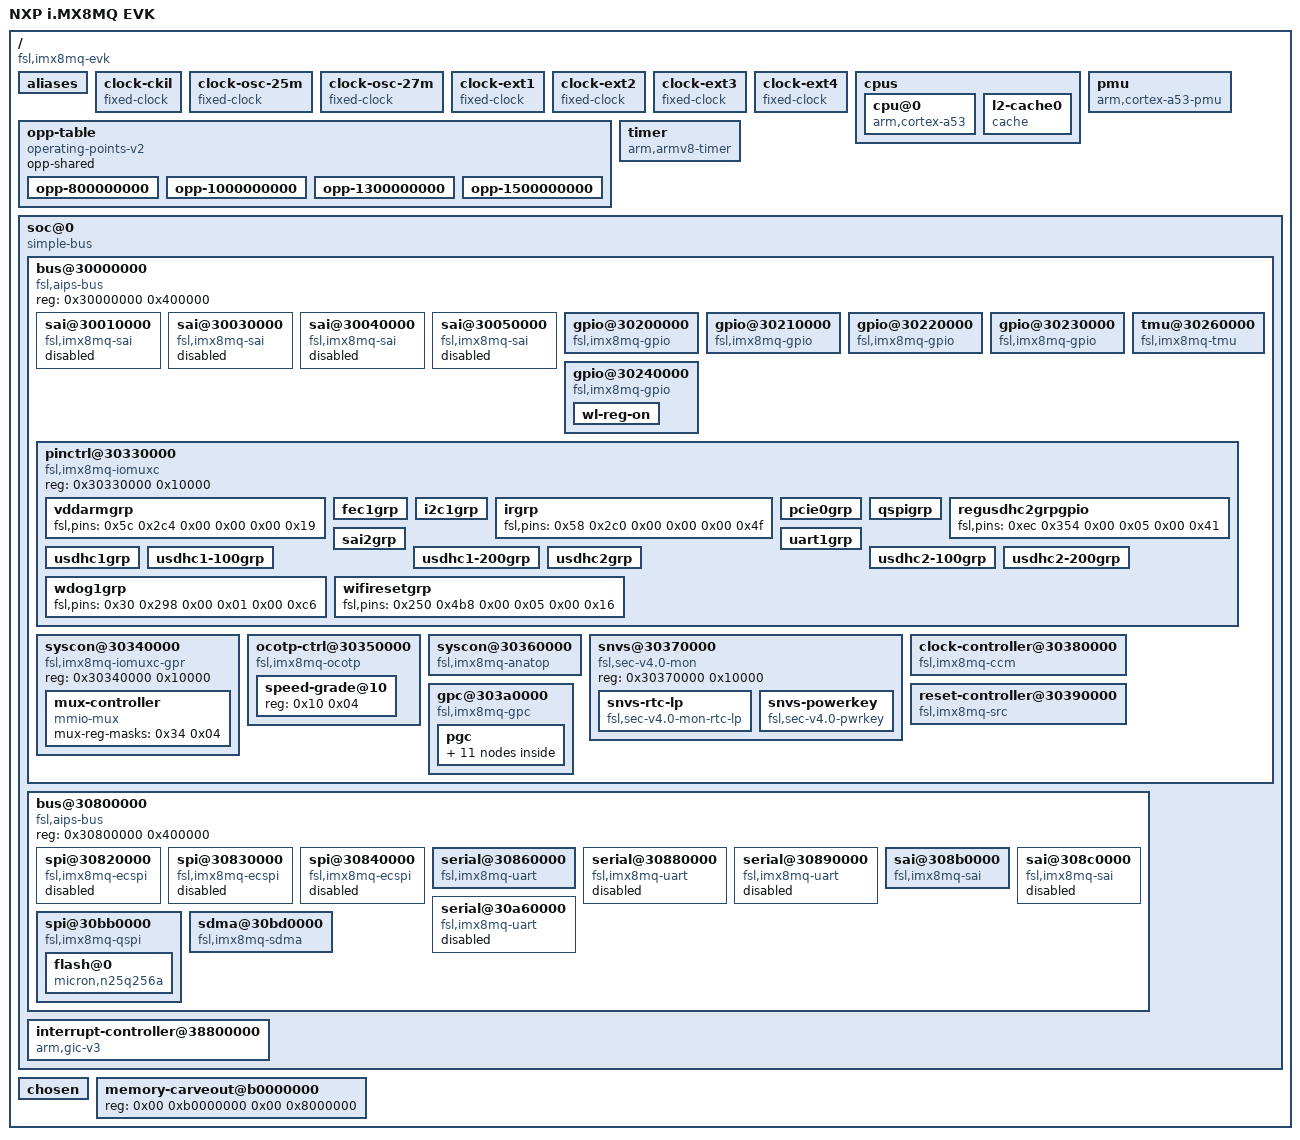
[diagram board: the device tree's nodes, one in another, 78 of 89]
/dts-v1/;

/ {
	interrupt-parent = <0x01>;
	#address-cells = <0x02>;
	#size-cells = <0x02>;
	model = "NXP i.MX8MQ EVK";
	compatible = "fsl,imx8mq-evk\0fsl,imx8mq";

	aliases {
		gpio0 = "/soc@0/bus@30000000/gpio@30200000";
		gpio1 = "/soc@0/bus@30000000/gpio@30210000";
		gpio2 = "/soc@0/bus@30000000/gpio@30220000";
		gpio3 = "/soc@0/bus@30000000/gpio@30230000";
		gpio4 = "/soc@0/bus@30000000/gpio@30240000";
		i2c0 = "/soc@0/bus@30800000/i2c@30a20000";
		i2c1 = "/soc@0/bus@30800000/i2c@30a30000";
		i2c2 = "/soc@0/bus@30800000/i2c@30a40000";
		i2c3 = "/soc@0/bus@30800000/i2c@30a50000";
		serial0 = "/soc@0/bus@30800000/serial@30860000";
		serial1 = "/soc@0/bus@30800000/serial@30890000";
		serial2 = "/soc@0/bus@30800000/serial@30880000";
		serial3 = "/soc@0/bus@30800000/serial@30a60000";
		spi0 = "/soc@0/bus@30800000/spi@30820000";
		spi1 = "/soc@0/bus@30800000/spi@30830000";
		spi2 = "/soc@0/bus@30800000/spi@30840000";
	};

	clock-ckil {
		compatible = "fixed-clock";
		#clock-cells = <0x00>;
		clock-frequency = <0x8000>;
		clock-output-names = "ckil";
		phandle = <0x16>;
	};

	clock-osc-25m {
		compatible = "fixed-clock";
		#clock-cells = <0x00>;
		clock-frequency = <0x17d7840>;
		clock-output-names = "osc_25m";
		phandle = <0x17>;
	};

	clock-osc-27m {
		compatible = "fixed-clock";
		#clock-cells = <0x00>;
		clock-frequency = <0x19bfcc0>;
		clock-output-names = "osc_27m";
		phandle = <0x18>;
	};

	clock-ext1 {
		compatible = "fixed-clock";
		#clock-cells = <0x00>;
		clock-frequency = <0x7ed6b40>;
		clock-output-names = "clk_ext1";
		phandle = <0x19>;
	};

	clock-ext2 {
		compatible = "fixed-clock";
		#clock-cells = <0x00>;
		clock-frequency = <0x7ed6b40>;
		clock-output-names = "clk_ext2";
		phandle = <0x1a>;
	};

	clock-ext3 {
		compatible = "fixed-clock";
		#clock-cells = <0x00>;
		clock-frequency = <0x7ed6b40>;
		clock-output-names = "clk_ext3";
		phandle = <0x1b>;
	};

	clock-ext4 {
		compatible = "fixed-clock";
		#clock-cells = <0x00>;
		clock-frequency = <0x7ed6b40>;
		clock-output-names = "clk_ext4";
		phandle = <0x1c>;
	};

	cpus {
		#address-cells = <0x01>;
		#size-cells = <0x00>;

		cpu@0 {
			device_type = "cpu";
			compatible = "arm,cortex-a53";
			reg = <0x00>;
			clock-latency = <0xee6c>;
			clocks = <0x02 0x102>;
			enable-method = "psci";
			next-level-cache = <0x03>;
			operating-points-v2 = <0x04>;
			#cooling-cells = <0x02>;
			nvmem-cells = <0x05>;
			nvmem-cell-names = "speed_grade";
			cpu-supply = <0x06>;
			phandle = <0x08>;
		};

		l2-cache0 {
			compatible = "cache";
			phandle = <0x03>;
		};
	};

	opp-table {
		compatible = "operating-points-v2";
		opp-shared;
		phandle = <0x04>;

		opp-800000000 {
			opp-hz = <0x00 0x2faf0800>;
			opp-microvolt = <0xdbba0>;
			opp-supported-hw = <0x0f 0x04>;
			clock-latency-ns = <0x249f0>;
			opp-suspend;
		};

		opp-1000000000 {
			opp-hz = <0x00 0x3b9aca00>;
			opp-microvolt = <0xdbba0>;
			opp-supported-hw = <0x0e 0x03>;
			clock-latency-ns = <0x249f0>;
			opp-suspend;
		};

		opp-1300000000 {
			opp-hz = <0x00 0x4d7c6d00>;
			opp-microvolt = <0xf4240>;
			opp-supported-hw = <0x0c 0x04>;
			clock-latency-ns = <0x249f0>;
			opp-suspend;
		};

		opp-1500000000 {
			opp-hz = <0x00 0x59682f00>;
			opp-microvolt = <0xf4240>;
			opp-supported-hw = <0x08 0x03>;
			clock-latency-ns = <0x249f0>;
			opp-suspend;
		};
	};

	pmu {
		compatible = "arm,cortex-a53-pmu";
		interrupts = <0x01 0x07 0x04>;
		interrupt-parent = <0x07>;
		interrupt-affinity = <0x08 0x09 0x0a 0x0b>;
	};

	timer {
		compatible = "arm,armv8-timer";
		interrupts = <0x01 0x0d 0x08 0x01 0x0e 0x08 0x01 0x0b 0x08 0x01 0x0a 0x08>;
		interrupt-parent = <0x07>;
		arm,no-tick-in-suspend;
	};

	soc@0 {
		compatible = "simple-bus";
		#address-cells = <0x01>;
		#size-cells = <0x01>;
		ranges = <0x00 0x00 0x00 0x3e000000>;
		dma-ranges = <0x40000000 0x00 0x40000000 0xc0000000>;

		bus@30000000 {
			compatible = "fsl,aips-bus\0simple-bus";
			reg = <0x30000000 0x400000>;
			#address-cells = <0x01>;
			#size-cells = <0x01>;
			ranges = <0x30000000 0x30000000 0x400000>;

			sai@30010000 {
				#sound-dai-cells = <0x00>;
				compatible = "fsl,imx8mq-sai";
				reg = <0x30010000 0x10000>;
				interrupts = <0x00 0x5f 0x04>;
				clocks = <0x02 0xee 0x02 0xc4 0x02 0x00 0x02 0x00>;
				clock-names = "bus\0mclk1\0mclk2\0mclk3";
				dmas = <0x10 0x08 0x18 0x00 0x11 0x09 0x18 0x00>;
				dma-names = "rx\0tx";
				status = "disabled";
			};

			sai@30030000 {
				#sound-dai-cells = <0x00>;
				compatible = "fsl,imx8mq-sai";
				reg = <0x30030000 0x10000>;
				interrupts = <0x00 0x5a 0x04>;
				clocks = <0x02 0xf3 0x02 0xc9 0x02 0x00 0x02 0x00>;
				clock-names = "bus\0mclk1\0mclk2\0mclk3";
				dmas = <0x10 0x04 0x18 0x00 0x10 0x05 0x18 0x00>;
				dma-names = "rx\0tx";
				status = "disabled";
			};

			sai@30040000 {
				#sound-dai-cells = <0x00>;
				compatible = "fsl,imx8mq-sai";
				reg = <0x30040000 0x10000>;
				interrupts = <0x00 0x5a 0x04>;
				clocks = <0x02 0xf2 0x02 0xc8 0x02 0x00 0x02 0x00>;
				clock-names = "bus\0mclk1\0mclk2\0mclk3";
				dmas = <0x10 0x02 0x18 0x00 0x10 0x03 0x18 0x00>;
				dma-names = "rx\0tx";
				status = "disabled";
			};

			sai@30050000 {
				#sound-dai-cells = <0x00>;
				compatible = "fsl,imx8mq-sai";
				reg = <0x30050000 0x10000>;
				interrupts = <0x00 0x64 0x04>;
				clocks = <0x02 0xf1 0x02 0xc7 0x02 0x00 0x02 0x00>;
				clock-names = "bus\0mclk1\0mclk2\0mclk3";
				dmas = <0x10 0x00 0x18 0x00 0x10 0x01 0x18 0x00>;
				dma-names = "rx\0tx";
				status = "disabled";
			};

			gpio@30200000 {
				compatible = "fsl,imx8mq-gpio\0fsl,imx35-gpio";
				reg = <0x30200000 0x10000>;
				interrupts = <0x00 0x40 0x04 0x00 0x41 0x04>;
				clocks = <0x02 0x103>;
				gpio-controller;
				#gpio-cells = <0x02>;
				interrupt-controller;
				#interrupt-cells = <0x02>;
				gpio-ranges = <0x12 0x00 0x0a 0x1e>;
				phandle = <0x2f>;
			};

			gpio@30210000 {
				compatible = "fsl,imx8mq-gpio\0fsl,imx35-gpio";
				reg = <0x30210000 0x10000>;
				interrupts = <0x00 0x42 0x04 0x00 0x43 0x04>;
				clocks = <0x02 0x104>;
				gpio-controller;
				#gpio-cells = <0x02>;
				interrupt-controller;
				#interrupt-cells = <0x02>;
				gpio-ranges = <0x12 0x00 0x28 0x15>;
				phandle = <0x2a>;
			};

			gpio@30220000 {
				compatible = "fsl,imx8mq-gpio\0fsl,imx35-gpio";
				reg = <0x30220000 0x10000>;
				interrupts = <0x00 0x44 0x04 0x00 0x45 0x04>;
				clocks = <0x02 0x105>;
				gpio-controller;
				#gpio-cells = <0x02>;
				interrupt-controller;
				#interrupt-cells = <0x02>;
				gpio-ranges = <0x12 0x00 0x3d 0x1a>;
			};

			gpio@30230000 {
				compatible = "fsl,imx8mq-gpio\0fsl,imx35-gpio";
				reg = <0x30230000 0x10000>;
				interrupts = <0x00 0x46 0x04 0x00 0x47 0x04>;
				clocks = <0x02 0x106>;
				gpio-controller;
				#gpio-cells = <0x02>;
				interrupt-controller;
				#interrupt-cells = <0x02>;
				gpio-ranges = <0x12 0x00 0x57 0x20>;
			};

			gpio@30240000 {
				compatible = "fsl,imx8mq-gpio\0fsl,imx35-gpio";
				reg = <0x30240000 0x10000>;
				interrupts = <0x00 0x48 0x04 0x00 0x49 0x04>;
				clocks = <0x02 0x107>;
				gpio-controller;
				#gpio-cells = <0x02>;
				interrupt-controller;
				#interrupt-cells = <0x02>;
				gpio-ranges = <0x12 0x00 0x77 0x1e>;
				pinctrl-names = "default";
				pinctrl-0 = <0x13>;
				phandle = <0x38>;

				wl-reg-on {
					gpio-hog;
					gpios = <0x1d 0x00>;
					output-high;
				};
			};

			tmu@30260000 {
				compatible = "fsl,imx8mq-tmu";
				reg = <0x30260000 0x10000>;
				interrupt = <0x00 0x31 0x04>;
				clocks = <0x02 0xf6>;
				little-endian;
				fsl,tmu-range = <0xb0000 0xa0026 0x80048 0x70061>;
				fsl,tmu-calibration = <0x00 0x23 0x01 0x29 0x02 0x2f 0x03 0x35 0x04 0x3d 0x05 0x43 0x06 0x4b 0x07 0x51 0x08 0x57 0x09 0x5f 0x0a 0x67 0x0b 0x6f 0x10000 0x1b 0x10001 0x23 0x10002 0x2b 0x10003 0x33 0x10004 0x3b 0x10005 0x43 0x10006 0x4b 0x10007 0x55 0x10008 0x5d 0x10009 0x67 0x1000a 0x70 0x20000 0x17 0x20001 0x23 0x20002 0x2d 0x20003 0x37 0x20004 0x41 0x20005 0x4b 0x20006 0x57 0x20007 0x63 0x20008 0x6f 0x30000 0x15 0x30001 0x21 0x30002 0x2d 0x30003 0x39 0x30004 0x45 0x30005 0x53 0x30006 0x5f 0x30007 0x71>;
				#thermal-sensor-cells = <0x01>;
				phandle = <0x0c>;
			};

			pinctrl@30330000 {
				compatible = "fsl,imx8mq-iomuxc";
				reg = <0x30330000 0x10000>;
				phandle = <0x12>;

				vddarmgrp {
					fsl,pins = <0x5c 0x2c4 0x00 0x00 0x00 0x19>;
					phandle = <0x3c>;
				};

				fec1grp {
					fsl,pins = <0x68 0x2d0 0x00 0x00 0x00 0x03 0x6c 0x2d4 0x4c0 0x00 0x01 0x23 0x70 0x2d8 0x00 0x00 0x00 0x1f 0x74 0x2dc 0x00 0x00 0x00 0x1f 0x78 0x2e0 0x00 0x00 0x00 0x1f 0x7c 0x2e4 0x00 0x00 0x00 0x1f 0x9c 0x304 0x00 0x00 0x00 0x91 0x98 0x300 0x00 0x00 0x00 0x91 0x94 0x2fc 0x00 0x00 0x00 0x91 0x90 0x2f8 0x00 0x00 0x00 0x91 0x84 0x2ec 0x00 0x00 0x00 0x1f 0x8c 0x2f4 0x00 0x00 0x00 0x91 0x88 0x2f0 0x00 0x00 0x00 0x91 0x80 0x2e8 0x00 0x00 0x00 0x1f 0x4c 0x2b4 0x00 0x00 0x00 0x19>;
					phandle = <0x2d>;
				};

				i2c1grp {
					fsl,pins = <0x214 0x47c 0x00 0x00 0x00 0x4000007f 0x218 0x480 0x00 0x00 0x00 0x4000007f>;
					phandle = <0x22>;
				};

				irgrp {
					fsl,pins = <0x58 0x2c0 0x00 0x00 0x00 0x4f>;
					phandle = <0x3d>;
				};

				pcie0grp {
					fsl,pins = <0x22c 0x494 0x524 0x02 0x00 0x76 0x24c 0x4b4 0x00 0x05 0x00 0x16>;
					phandle = <0x37>;
				};

				qspigrp {
					fsl,pins = <0xf4 0x35c 0x00 0x01 0x00 0x82 0xf8 0x360 0x00 0x01 0x00 0x82 0x10c 0x374 0x00 0x01 0x00 0x82 0x110 0x378 0x00 0x01 0x00 0x82 0x114 0x37c 0x00 0x01 0x00 0x82 0x118 0x380 0x00 0x01 0x00 0x82>;
					phandle = <0x2c>;
				};

				regusdhc2grpgpio {
					fsl,pins = <0xec 0x354 0x00 0x05 0x00 0x41>;
					phandle = <0x3b>;
				};

				sai2grp {
					fsl,pins = <0x1bc 0x424 0x00 0x00 0x00 0xd6 0x1c0 0x428 0x00 0x00 0x00 0xd6 0x1c8 0x430 0x00 0x00 0x00 0xd6 0x1c4 0x42c 0x00 0x00 0x00 0xd6 0x48 0x2b0 0x00 0x00 0x00 0xd6>;
					phandle = <0x20>;
				};

				uart1grp {
					fsl,pins = <0x234 0x49c 0x4f4 0x00 0x00 0x49 0x238 0x4a0 0x00 0x00 0x00 0x49>;
					phandle = <0x1f>;
				};

				usdhc1grp {
					fsl,pins = <0xa0 0x308 0x00 0x00 0x00 0x83 0xa4 0x30c 0x00 0x00 0x00 0xc3 0xa8 0x310 0x00 0x00 0x00 0xc3 0xac 0x314 0x00 0x00 0x00 0xc3 0xb0 0x318 0x00 0x00 0x00 0xc3 0xb4 0x31c 0x00 0x00 0x00 0xc3 0xb8 0x320 0x00 0x00 0x00 0xc3 0xbc 0x324 0x00 0x00 0x00 0xc3 0xc0 0x328 0x00 0x00 0x00 0xc3 0xc4 0x32c 0x00 0x00 0x00 0xc3 0xcc 0x334 0x00 0x00 0x00 0x83 0xc8 0x330 0x00 0x00 0x00 0xc1>;
					phandle = <0x23>;
				};

				usdhc1-100grp {
					fsl,pins = <0xa0 0x308 0x00 0x00 0x00 0x8d 0xa4 0x30c 0x00 0x00 0x00 0xcd 0xa8 0x310 0x00 0x00 0x00 0xcd 0xac 0x314 0x00 0x00 0x00 0xcd 0xb0 0x318 0x00 0x00 0x00 0xcd 0xb4 0x31c 0x00 0x00 0x00 0xcd 0xb8 0x320 0x00 0x00 0x00 0xcd 0xbc 0x324 0x00 0x00 0x00 0xcd 0xc0 0x328 0x00 0x00 0x00 0xcd 0xc4 0x32c 0x00 0x00 0x00 0xcd 0xcc 0x334 0x00 0x00 0x00 0x8d 0xc8 0x330 0x00 0x00 0x00 0xc1>;
					phandle = <0x24>;
				};

				usdhc1-200grp {
					fsl,pins = <0xa0 0x308 0x00 0x00 0x00 0x9f 0xa4 0x30c 0x00 0x00 0x00 0xdf 0xa8 0x310 0x00 0x00 0x00 0xdf 0xac 0x314 0x00 0x00 0x00 0xdf 0xb0 0x318 0x00 0x00 0x00 0xdf 0xb4 0x31c 0x00 0x00 0x00 0xdf 0xb8 0x320 0x00 0x00 0x00 0xdf 0xbc 0x324 0x00 0x00 0x00 0xdf 0xc0 0x328 0x00 0x00 0x00 0xdf 0xc4 0x32c 0x00 0x00 0x00 0xdf 0xcc 0x334 0x00 0x00 0x00 0x9f 0xc8 0x330 0x00 0x00 0x00 0xc1>;
					phandle = <0x25>;
				};

				usdhc2grp {
					fsl,pins = <0xd4 0x33c 0x00 0x00 0x00 0x83 0xd8 0x340 0x00 0x00 0x00 0xc3 0xdc 0x344 0x00 0x00 0x00 0xc3 0xe0 0x348 0x00 0x00 0x00 0xc3 0xe4 0x34c 0x00 0x00 0x00 0xc3 0xe8 0x350 0x00 0x00 0x00 0xc3 0x38 0x2a0 0x00 0x01 0x00 0xc1>;
					phandle = <0x27>;
				};

				usdhc2-100grp {
					fsl,pins = <0xd4 0x33c 0x00 0x00 0x00 0x85 0xd8 0x340 0x00 0x00 0x00 0xc5 0xdc 0x344 0x00 0x00 0x00 0xc5 0xe0 0x348 0x00 0x00 0x00 0xc5 0xe4 0x34c 0x00 0x00 0x00 0xc5 0xe8 0x350 0x00 0x00 0x00 0xc5 0x38 0x2a0 0x00 0x01 0x00 0xc1>;
					phandle = <0x28>;
				};

				usdhc2-200grp {
					fsl,pins = <0xd4 0x33c 0x00 0x00 0x00 0x87 0xd8 0x340 0x00 0x00 0x00 0xc7 0xdc 0x344 0x00 0x00 0x00 0xc7 0xe0 0x348 0x00 0x00 0x00 0xc7 0xe4 0x34c 0x00 0x00 0x00 0xc7 0xe8 0x350 0x00 0x00 0x00 0xc7 0x38 0x2a0 0x00 0x01 0x00 0xc1>;
					phandle = <0x29>;
				};

				wdog1grp {
					fsl,pins = <0x30 0x298 0x00 0x01 0x00 0xc6>;
					phandle = <0x14>;
				};

				wifiresetgrp {
					fsl,pins = <0x250 0x4b8 0x00 0x05 0x00 0x16>;
					phandle = <0x13>;
				};
			};

			syscon@30340000 {
				compatible = "fsl,imx8mq-iomuxc-gpr\0fsl,imx6q-iomuxc-gpr\0syscon\0simple-mfd";
				reg = <0x30340000 0x10000>;

				mux-controller {
					compatible = "mmio-mux";
					#mux-control-cells = <0x01>;
					mux-reg-masks = <0x34 0x04>;
				};
			};

			ocotp-ctrl@30350000 {
				compatible = "fsl,imx8mq-ocotp\0syscon";
				reg = <0x30350000 0x10000>;
				clocks = <0x02 0xfa>;
				#address-cells = <0x01>;
				#size-cells = <0x01>;

				speed-grade@10 {
					reg = <0x10 0x04>;
					phandle = <0x05>;
				};
			};

			syscon@30360000 {
				compatible = "fsl,imx8mq-anatop\0syscon";
				reg = <0x30360000 0x10000>;
				interrupts = <0x00 0x31 0x04>;
			};

			snvs@30370000 {
				compatible = "fsl,sec-v4.0-mon\0syscon\0simple-mfd";
				reg = <0x30370000 0x10000>;
				phandle = <0x15>;

				snvs-rtc-lp {
					compatible = "fsl,sec-v4.0-mon-rtc-lp";
					regmap = <0x15>;
					offset = <0x34>;
					interrupts = <0x00 0x13 0x04 0x00 0x14 0x04>;
					clocks = <0x02 0x108>;
					clock-names = "snvs-rtc";
				};

				snvs-powerkey {
					compatible = "fsl,sec-v4.0-pwrkey";
					regmap = <0x15>;
					interrupts = <0x00 0x04 0x04>;
					clocks = <0x02 0x108>;
					clock-names = "snvs-pwrkey";
					linux,keycode = <0x74>;
					wakeup-source;
					status = "okay";
				};
			};

			clock-controller@30380000 {
				compatible = "fsl,imx8mq-ccm";
				reg = <0x30380000 0x10000>;
				interrupts = <0x00 0x55 0x04 0x00 0x56 0x04>;
				#clock-cells = <0x01>;
				clocks = <0x16 0x17 0x18 0x19 0x1a 0x1b 0x1c>;
				clock-names = "ckil\0osc_25m\0osc_27m\0clk_ext1\0clk_ext2\0clk_ext3\0clk_ext4";
				assigned-clocks = <0x02 0x58 0x02 0x121 0x02 0x71>;
				assigned-clock-rates = <0x00 0x00 0x2faf0800>;
				assigned-clock-parents = <0x02 0x4e 0x02 0x0c>;
				phandle = <0x02>;
			};

			reset-controller@30390000 {
				compatible = "fsl,imx8mq-src\0syscon";
				reg = <0x30390000 0x10000>;
				interrupts = <0x00 0x59 0x04>;
				#reset-cells = <0x01>;
				phandle = <0x36>;
			};

			gpc@303a0000 {
				compatible = "fsl,imx8mq-gpc";
				reg = <0x303a0000 0x10000>;
				interrupt-parent = <0x07>;
				interrupt-controller;
				#interrupt-cells = <0x03>;
				phandle = <0x01>;

				pgc {
					#address-cells = <0x01>;
					#size-cells = <0x00>;

					power-domain@0 {
						#power-domain-cells = <0x00>;
						reg = <0x00>;
						phandle = <0x21>;
					};

					power-domain@1 {
						#power-domain-cells = <0x00>;
						reg = <0x01>;
						power-domains = <0x1d>;
						phandle = <0x35>;
					};

					power-domain@2 {
						#power-domain-cells = <0x00>;
						reg = <0x02>;
						phandle = <0x32>;
					};

					power-domain@3 {
						#power-domain-cells = <0x00>;
						reg = <0x03>;
						phandle = <0x34>;
					};

					power-domain@4 {
						#power-domain-cells = <0x00>;
						reg = <0x04>;
					};

					power-domain@5 {
						#power-domain-cells = <0x00>;
						reg = <0x05>;
						clocks = <0x02 0xd7 0x02 0x66 0x02 0x6f 0x02 0x70>;
						power-supply = <0x1e>;
						phandle = <0x30>;
					};

					power-domain@6 {
						#power-domain-cells = <0x00>;
						reg = <0x06>;
					};

					power-domain@7 {
						#power-domain-cells = <0x00>;
						reg = <0x07>;
					};

					power-domain@8 {
						#power-domain-cells = <0x00>;
						reg = <0x08>;
					};

					power-domain@9 {
						#power-domain-cells = <0x00>;
						reg = <0x09>;
					};

					power-domain@a {
						#power-domain-cells = <0x00>;
						reg = <0x0a>;
						phandle = <0x1d>;
					};
				};
			};
		};

		bus@30800000 {
			compatible = "fsl,aips-bus\0simple-bus";
			reg = <0x30800000 0x400000>;
			#address-cells = <0x01>;
			#size-cells = <0x01>;
			ranges = <0x30800000 0x30800000 0x400000 0x8000000 0x8000000 0x10000000>;

			spi@30820000 {
				#address-cells = <0x01>;
				#size-cells = <0x00>;
				compatible = "fsl,imx8mq-ecspi\0fsl,imx51-ecspi";
				reg = <0x30820000 0x10000>;
				interrupts = <0x00 0x1f 0x04>;
				clocks = <0x02 0xb3 0x02 0xb3>;
				clock-names = "ipg\0per";
				status = "disabled";
			};

			spi@30830000 {
				#address-cells = <0x01>;
				#size-cells = <0x00>;
				compatible = "fsl,imx8mq-ecspi\0fsl,imx51-ecspi";
				reg = <0x30830000 0x10000>;
				interrupts = <0x00 0x20 0x04>;
				clocks = <0x02 0xb4 0x02 0xb4>;
				clock-names = "ipg\0per";
				status = "disabled";
			};

			spi@30840000 {
				#address-cells = <0x01>;
				#size-cells = <0x00>;
				compatible = "fsl,imx8mq-ecspi\0fsl,imx51-ecspi";
				reg = <0x30840000 0x10000>;
				interrupts = <0x00 0x21 0x04>;
				clocks = <0x02 0xb5 0x02 0xb5>;
				clock-names = "ipg\0per";
				status = "disabled";
			};

			serial@30860000 {
				compatible = "fsl,imx8mq-uart\0fsl,imx6q-uart";
				reg = <0x30860000 0x10000>;
				interrupts = <0x00 0x1a 0x04>;
				clocks = <0x02 0xca 0x02 0xca>;
				clock-names = "ipg\0per";
				status = "okay";
				pinctrl-names = "default";
				pinctrl-0 = <0x1f>;
			};

			serial@30880000 {
				compatible = "fsl,imx8mq-uart\0fsl,imx6q-uart";
				reg = <0x30880000 0x10000>;
				interrupts = <0x00 0x1c 0x04>;
				clocks = <0x02 0xcc 0x02 0xcc>;
				clock-names = "ipg\0per";
				status = "disabled";
			};

			serial@30890000 {
				compatible = "fsl,imx8mq-uart\0fsl,imx6q-uart";
				reg = <0x30890000 0x10000>;
				interrupts = <0x00 0x1b 0x04>;
				clocks = <0x02 0xcb 0x02 0xcb>;
				clock-names = "ipg\0per";
				status = "disabled";
			};

			sai@308b0000 {
				#sound-dai-cells = <0x00>;
				compatible = "fsl,imx8mq-sai";
				reg = <0x308b0000 0x10000>;
				interrupts = <0x00 0x60 0x04>;
				clocks = <0x02 0xef 0x02 0xc5 0x02 0x00 0x02 0x00>;
				clock-names = "bus\0mclk1\0mclk2\0mclk3";
				dmas = <0x11 0x0a 0x18 0x00 0x11 0x0b 0x18 0x00>;
				dma-names = "rx\0tx";
				status = "okay";
				pinctrl-names = "default";
				pinctrl-0 = <0x20>;
				assigned-clocks = <0x02 0x1a 0x02 0x82>;
				assigned-clock-parents = <0x02 0x19 0x02 0x1b>;
				assigned-clock-rates = <0x00 0x1770000>;
				phandle = <0x3f>;
			};

			sai@308c0000 {
				#sound-dai-cells = <0x00>;
				compatible = "fsl,imx8mq-sai";
				reg = <0x308c0000 0x10000>;
				interrupts = <0x00 0x32 0x04>;
				clocks = <0x02 0xf0 0x02 0xc6 0x02 0x00 0x02 0x00>;
				clock-names = "bus\0mclk1\0mclk2\0mclk3";
				dmas = <0x11 0x0c 0x18 0x00 0x11 0x0d 0x18 0x00>;
				dma-names = "rx\0tx";
				status = "disabled";
			};

			serial@30a60000 {
				compatible = "fsl,imx8mq-uart\0fsl,imx6q-uart";
				reg = <0x30a60000 0x10000>;
				interrupts = <0x00 0x1d 0x04>;
				clocks = <0x02 0xcd 0x02 0xcd>;
				clock-names = "ipg\0per";
				status = "disabled";
			};

			spi@30bb0000 {
				#address-cells = <0x01>;
				#size-cells = <0x00>;
				compatible = "fsl,imx8mq-qspi\0fsl,imx7d-qspi";
				reg = <0x30bb0000 0x10000 0x8000000 0x10000000>;
				reg-names = "QuadSPI\0QuadSPI-memory";
				interrupts = <0x00 0x6b 0x04>;
				clocks = <0x02 0xc3 0x02 0xc3>;
				clock-names = "qspi_en\0qspi";
				status = "okay";
				pinctrl-names = "default";
				pinctrl-0 = <0x2c>;

				flash@0 {
					reg = <0x00>;
					#address-cells = <0x01>;
					#size-cells = <0x01>;
					compatible = "micron,n25q256a\0jedec,spi-nor";
					spi-max-frequency = <0x1ba8140>;
				};
			};

			sdma@30bd0000 {
				compatible = "fsl,imx8mq-sdma\0fsl,imx7d-sdma";
				reg = <0x30bd0000 0x10000>;
				interrupts = <0x00 0x02 0x04>;
				clocks = <0x02 0xe3 0x02 0x74>;
				clock-names = "ipg\0ahb";
				#dma-cells = <0x03>;
				fsl,sdma-ram-script-name = "imx/sdma/sdma-imx7d.bin";
				phandle = <0x11>;
			};
		};

		interrupt-controller@38800000 {
			compatible = "arm,gic-v3";
			reg = <0x38800000 0x10000 0x38880000 0xc0000 0x31000000 0x2000 0x31010000 0x2000 0x31020000 0x2000>;
			#interrupt-cells = <0x03>;
			interrupt-controller;
			interrupts = <0x01 0x09 0x04>;
			interrupt-parent = <0x07>;
			phandle = <0x07>;
		};
	};

	chosen {
		stdout-path = "/soc@0/bus@30800000/serial@30860000";
	};

	memory-carveout@b0000000 {
		device_type = "memory";
		reg = <0x00 0xb0000000 0x00 0x8000000>;
	};
};
